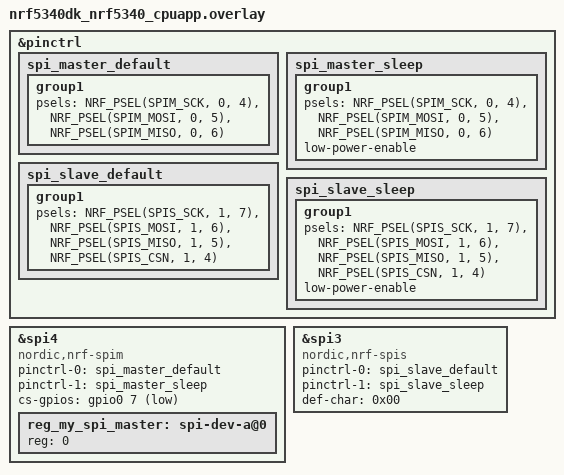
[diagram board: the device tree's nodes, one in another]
&pinctrl {
	spi_master_default: spi_master_default {
		group1 {
			psels = <NRF_PSEL(SPIM_SCK, 0, 4)>,
					<NRF_PSEL(SPIM_MOSI, 0, 5)>,
					<NRF_PSEL(SPIM_MISO, 0, 6)>;
		};
	};

	spi_master_sleep: spi_master_sleep {
		group1 {
			psels = <NRF_PSEL(SPIM_SCK, 0, 4)>,
					<NRF_PSEL(SPIM_MOSI, 0, 5)>,
					<NRF_PSEL(SPIM_MISO, 0, 6)>;
			low-power-enable;
		};
	};

	spi_slave_default: spi_slave_default {
		group1 {
			psels = <NRF_PSEL(SPIS_SCK, 1, 7)>,
					<NRF_PSEL(SPIS_MOSI, 1, 6)>,
					<NRF_PSEL(SPIS_MISO, 1, 5)>,
					<NRF_PSEL(SPIS_CSN, 1, 4)>;
		};
	};

	spi_slave_sleep: spi_slave_sleep {
		group1 {
			psels = <NRF_PSEL(SPIS_SCK, 1, 7)>,
					<NRF_PSEL(SPIS_MOSI, 1, 6)>,
					<NRF_PSEL(SPIS_MISO, 1, 5)>,
					<NRF_PSEL(SPIS_CSN, 1, 4)>;
			low-power-enable;
		};
	};
};

my_spi_master: &spi4 {
	compatible = "nordic,nrf-spim";
	status = "okay";
	pinctrl-0 = <&spi_master_default>;
	pinctrl-1 = <&spi_master_sleep>;
	pinctrl-names = "default", "sleep";
	cs-gpios = <&gpio0 7 GPIO_ACTIVE_LOW>;
	reg_my_spi_master:  spi-dev-a@0 {
		reg = <0>;
	};
};

my_spi_slave: &spi3 {
	compatible = "nordic,nrf-spis";
	status = "okay";
	pinctrl-0 = <&spi_slave_default>;
	pinctrl-1 = <&spi_slave_sleep>;
	pinctrl-names = "default", "sleep";
	def-char = <0x00>;
};
